VERSION ""
NS_ :

BS_:
BU_: Teaching
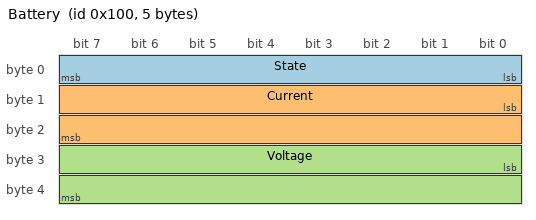
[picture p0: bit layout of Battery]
BO_ 256 Battery: 5 Teaching
 SG_ State : 0|8@1+ (1,0) [0|255] "" Teaching
 SG_ Current : 8|16@1- (0.1,0) [-3276.8|3276.7] "A" Teaching
 SG_ Voltage : 24|16@1+ (0.1,0) [0|6553.5] "V" Teaching
BA_DEF_ BO_ "GenMsgCycleTime" INT 0 2147483647;
BA_ "GenMsgCycleTime" BO_ 256 1000;
